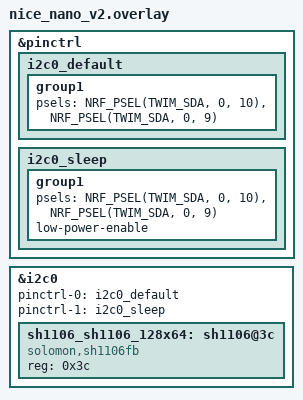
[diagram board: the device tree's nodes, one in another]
&pinctrl {
    i2c0_default: i2c0_default {
        group1 {
            psels = <NRF_PSEL(TWIM_SDA, 0, 10)>,
                    <NRF_PSEL(TWIM_SDA, 0, 9)>;
        };
    };

    i2c0_sleep: i2c0_sleep {
        group1 {
            psels = <NRF_PSEL(TWIM_SDA, 0, 10)>,
                    <NRF_PSEL(TWIM_SDA, 0, 9)>;
            low-power-enable;
        };
    };
};

&i2c0 {
    pinctrl-0 = <&i2c0_default>;
    pinctrl-1 = <&i2c0_sleep>;
    pinctrl-names = "default", "sleep";
    status="okay";

    sh1106_sh1106_128x64: sh1106@3c {
		compatible = "solomon,sh1106fb";
		reg = <0x3c>;
    };
};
